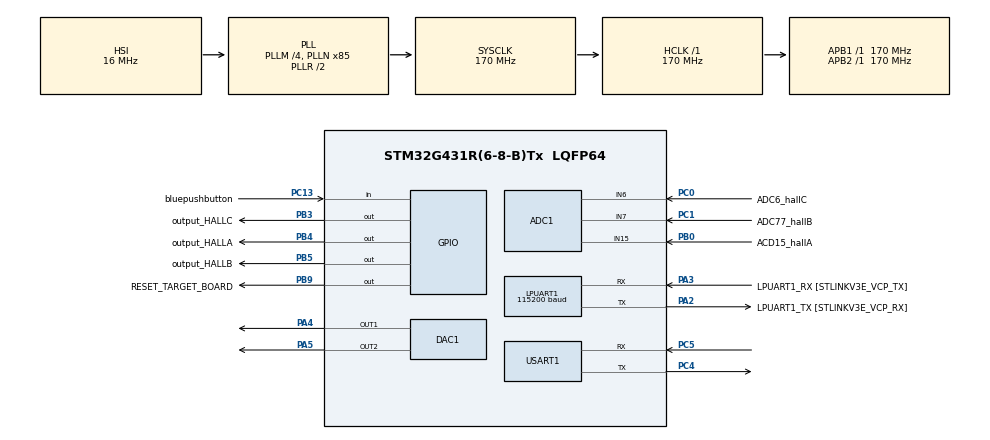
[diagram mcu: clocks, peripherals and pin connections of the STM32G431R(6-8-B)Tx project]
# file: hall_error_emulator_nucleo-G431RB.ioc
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ADC1.Channel-0\#ChannelRegularConversion=ADC_CHANNEL_15
ADC1.Channel-1\#ChannelRegularConversion=ADC_CHANNEL_7
ADC1.Channel-2\#ChannelRegularConversion=ADC_CHANNEL_6
ADC1.ContinuousConvMode=ENABLE
ADC1.DMAContinuousRequests=ENABLE
ADC1.ExternalTrigConv=ADC_EXTERNALTRIG_T8_TRGO
ADC1.NbrOfConversion=3
ADC1.NbrOfConversionFlag=1
ADC1.OffsetNumber-0\#ChannelRegularConversion=ADC_OFFSET_NONE
ADC1.OffsetNumber-1\#ChannelRegularConversion=ADC_OFFSET_NONE
ADC1.OffsetNumber-2\#ChannelRegularConversion=ADC_OFFSET_NONE
ADC1.Rank-0\#ChannelRegularConversion=1
ADC1.Rank-1\#ChannelRegularConversion=2
ADC1.Rank-2\#ChannelRegularConversion=3
ADC1.SamplingTime-0\#ChannelRegularConversion=ADC_SAMPLETIME_2CYCLES_5
ADC1.SamplingTime-1\#ChannelRegularConversion=ADC_SAMPLETIME_2CYCLES_5
ADC1.SamplingTime-2\#ChannelRegularConversion=ADC_SAMPLETIME_2CYCLES_5
ADC1.master=1
DAC1.DAC_Channel-DAC_OUT2=DAC_CHANNEL_2
DAC1.DAC_Trigger_OUT1-DAC_OUT1=DAC_TRIGGER_T8_TRGO
DAC1.DAC_Trigger_OUT2-DAC_OUT2=DAC_TRIGGER_T8_TRGO
Dma.ADC1.4.Direction=DMA_PERIPH_TO_MEMORY
Dma.ADC1.4.EventEnable=DISABLE
Dma.ADC1.4.Instance=DMA1_Channel5
Dma.ADC1.4.MemDataAlignment=DMA_MDATAALIGN_WORD
Dma.ADC1.4.MemInc=DMA_MINC_ENABLE
Dma.ADC1.4.Mode=DMA_CIRCULAR
Dma.ADC1.4.PeriphDataAlignment=DMA_PDATAALIGN_WORD
Dma.ADC1.4.PeriphInc=DMA_PINC_DISABLE
Dma.ADC1.4.Polarity=HAL_DMAMUX_REQ_GEN_RISING
Dma.ADC1.4.Priority=DMA_PRIORITY_LOW
Dma.ADC1.4.RequestNumber=1
Dma.ADC1.4.SignalID=NONE
Dma.ADC1.4.SyncEnable=DISABLE
Dma.ADC1.4.SyncPolarity=HAL_DMAMUX_SYNC_NO_EVENT
Dma.ADC1.4.SyncRequestNumber=1
Dma.ADC1.4.SyncSignalID=NONE
Dma.DAC1_CH1.2.Direction=DMA_MEMORY_TO_PERIPH
Dma.DAC1_CH1.2.EventEnable=DISABLE
Dma.DAC1_CH1.2.Instance=DMA1_Channel3
Dma.DAC1_CH1.2.MemDataAlignment=DMA_MDATAALIGN_WORD
Dma.DAC1_CH1.2.MemInc=DMA_MINC_ENABLE
Dma.DAC1_CH1.2.Mode=DMA_CIRCULAR
Dma.DAC1_CH1.2.PeriphDataAlignment=DMA_PDATAALIGN_WORD
Dma.DAC1_CH1.2.PeriphInc=DMA_PINC_DISABLE
Dma.DAC1_CH1.2.Polarity=HAL_DMAMUX_REQ_GEN_RISING
Dma.DAC1_CH1.2.Priority=DMA_PRIORITY_MEDIUM
Dma.DAC1_CH1.2.RequestNumber=1
Dma.DAC1_CH1.2.SignalID=NONE
Dma.DAC1_CH1.2.SyncEnable=DISABLE
Dma.DAC1_CH1.2.SyncPolarity=HAL_DMAMUX_SYNC_NO_EVENT
Dma.DAC1_CH1.2.SyncRequestNumber=1
Dma.DAC1_CH1.2.SyncSignalID=NONE
Dma.DAC1_CH2.3.Direction=DMA_MEMORY_TO_PERIPH
Dma.DAC1_CH2.3.EventEnable=DISABLE
Dma.DAC1_CH2.3.Instance=DMA1_Channel4
Dma.DAC1_CH2.3.MemDataAlignment=DMA_MDATAALIGN_WORD
Dma.DAC1_CH2.3.MemInc=DMA_MINC_ENABLE
Dma.DAC1_CH2.3.Mode=DMA_CIRCULAR
Dma.DAC1_CH2.3.PeriphDataAlignment=DMA_PDATAALIGN_WORD
Dma.DAC1_CH2.3.PeriphInc=DMA_PINC_DISABLE
Dma.DAC1_CH2.3.Polarity=HAL_DMAMUX_REQ_GEN_RISING
Dma.DAC1_CH2.3.Priority=DMA_PRIORITY_MEDIUM
Dma.DAC1_CH2.3.RequestNumber=1
Dma.DAC1_CH2.3.SignalID=NONE
Dma.DAC1_CH2.3.SyncEnable=DISABLE
Dma.DAC1_CH2.3.SyncPolarity=HAL_DMAMUX_SYNC_NO_EVENT
Dma.DAC1_CH2.3.SyncRequestNumber=1
Dma.DAC1_CH2.3.SyncSignalID=NONE
Dma.LPUART1_RX.0.Direction=DMA_PERIPH_TO_MEMORY
Dma.LPUART1_RX.0.EventEnable=DISABLE
Dma.LPUART1_RX.0.Instance=DMA1_Channel1
Dma.LPUART1_RX.0.MemDataAlignment=DMA_MDATAALIGN_BYTE
Dma.LPUART1_RX.0.MemInc=DMA_MINC_ENABLE
Dma.LPUART1_RX.0.Mode=DMA_CIRCULAR
Dma.LPUART1_RX.0.PeriphDataAlignment=DMA_PDATAALIGN_BYTE
Dma.LPUART1_RX.0.PeriphInc=DMA_PINC_DISABLE
Dma.LPUART1_RX.0.Polarity=HAL_DMAMUX_REQ_GEN_RISING
Dma.LPUART1_RX.0.Priority=DMA_PRIORITY_LOW
Dma.LPUART1_RX.0.RequestNumber=1
Dma.LPUART1_RX.0.SignalID=NONE
Dma.LPUART1_RX.0.SyncEnable=DISABLE
Dma.LPUART1_RX.0.SyncPolarity=HAL_DMAMUX_SYNC_NO_EVENT
Dma.LPUART1_RX.0.SyncRequestNumber=1
Dma.LPUART1_RX.0.SyncSignalID=NONE
Dma.LPUART1_TX.1.Direction=DMA_MEMORY_TO_PERIPH
Dma.LPUART1_TX.1.EventEnable=DISABLE
Dma.LPUART1_TX.1.Instance=DMA1_Channel2
Dma.LPUART1_TX.1.MemDataAlignment=DMA_MDATAALIGN_BYTE
Dma.LPUART1_TX.1.MemInc=DMA_MINC_ENABLE
Dma.LPUART1_TX.1.Mode=DMA_NORMAL
Dma.LPUART1_TX.1.PeriphDataAlignment=DMA_PDATAALIGN_BYTE
Dma.LPUART1_TX.1.PeriphInc=DMA_PINC_DISABLE
Dma.LPUART1_TX.1.Polarity=HAL_DMAMUX_REQ_GEN_RISING
Dma.LPUART1_TX.1.Priority=DMA_PRIORITY_LOW
Dma.LPUART1_TX.1.RequestNumber=1
Dma.LPUART1_TX.1.SignalID=NONE
Dma.LPUART1_TX.1.SyncEnable=DISABLE
Dma.LPUART1_TX.1.SyncPolarity=HAL_DMAMUX_SYNC_NO_EVENT
Dma.LPUART1_TX.1.SyncRequestNumber=1
Dma.LPUART1_TX.1.SyncSignalID=NONE
Dma.Request0=LPUART1_RX
Dma.Request1=LPUART1_TX
Dma.Request2=DAC1_CH1
Dma.Request3=DAC1_CH2
Dma.Request4=ADC1
LPUART1.BaudRate=115200
Mcu.Family=STM32G4
Mcu.Name=STM32G431R(6-8-B)Tx
Mcu.Package=LQFP64
Mcu.UserConstants=PREESCALER_TIM8,170-1;COUNTER_TIM8,50-1
NVIC.DMA1_Channel1_IRQn=true\:0\:0\:false\:false\:true\:false\:true\:true
NVIC.DMA1_Channel2_IRQn=true\:0\:0\:false\:false\:true\:false\:true\:true
NVIC.DMA1_Channel3_IRQn=true\:0\:0\:false\:false\:true\:false\:true\:true
NVIC.DMA1_Channel4_IRQn=true\:0\:0\:false\:false\:true\:false\:true\:true
NVIC.DMA1_Channel5_IRQn=true\:0\:0\:false\:false\:true\:false\:true\:true
NVIC.LPUART1_IRQn=true\:1\:0\:true\:false\:true\:true\:true\:true
NVIC.PriorityGroup=NVIC_PRIORITYGROUP_4
NVIC.TIM8_UP_IRQn=true\:0\:0\:false\:false\:true\:true\:true\:true
PA13.GPIO_Label=T_SWDIO
PA13.Mode=Serial_Wire
PA13.Signal=SYS_JTMS-SWDIO
PA14.GPIO_Label=T_SWCLK
PA14.Mode=Serial_Wire
PA14.Signal=SYS_JTCK-SWCLK
PA2.GPIO_Label=LPUART1_TX [STLINKV3E_VCP_RX]
PA2.Mode=Asynchronous
PA2.Signal=LPUART1_TX
PA3.GPIO_Label=LPUART1_RX [STLINKV3E_VCP_TX]
PA3.Mode=Asynchronous
PA3.Signal=LPUART1_RX
PA4.Signal=COMP_DAC11_group
PA5.Signal=COMP_DAC12_group
PB0.GPIO_Label=ACD15_hallA
PB0.Mode=IN15-Single-Ended
PB0.Signal=ADC1_IN15
PB3.GPIO_Label=output_HALLC
PB3.Signal=GPIO_Output
PB4.GPIO_Label=output_HALLA
PB4.Signal=GPIO_Output
PB5.GPIO_Label=output_HALLB
PB5.Signal=GPIO_Output
PB9.GPIO_Label=RESET_TARGET_BOARD
PB9.GPIO_PuPd=GPIO_PULLUP
PB9.PinState=GPIO_PIN_SET
PB9.Signal=GPIO_Output
PC0.GPIO_Label=ADC6_hallC
PC0.Mode=IN6-Single-Ended
PC0.Signal=ADC1_IN6
PC1.GPIO_Label=ADC77_hallB
PC1.Mode=IN7-Single-Ended
PC1.Signal=ADC1_IN7
PC13.GPIO_Label=bluepushbutton
PC13.Signal=GPIO_Input
PC4.Mode=Asynchronous
PC4.Signal=USART1_TX
PC5.Mode=Asynchronous
PC5.Signal=USART1_RX
PF0-OSC_IN.Mode=HSE-External-Oscillator
PF0-OSC_IN.Signal=RCC_OSC_IN
PF1-OSC_OUT.Mode=HSE-External-Oscillator
PF1-OSC_OUT.Signal=RCC_OSC_OUT
ProjectManager.HeapSize=0x200
ProjectManager.StackSize=0x400
ProjectManager.TargetToolchain=STM32CubeIDE
RCC.ADC12Freq_Value=170000000
RCC.AHBFreq_Value=170000000
RCC.APB1Freq_Value=170000000
RCC.APB1TimFreq_Value=170000000
RCC.APB2Freq_Value=170000000
RCC.APB2TimFreq_Value=170000000
RCC.CortexFreq_Value=170000000
RCC.EXTERNAL_CLOCK_VALUE=12288000
RCC.HCLKFreq_Value=170000000
RCC.HSE_VALUE=24000000
RCC.HSI48_VALUE=48000000
RCC.HSI_VALUE=16000000
RCC.LSE_VALUE=32768
RCC.PLLM=RCC_PLLM_DIV4
RCC.PLLN=85
RCC.RTCClockSelection=RCC_RTCCLKSOURCE_LSE
RCC.SYSCLKFreq_VALUE=170000000
RCC.SYSCLKSource=RCC_SYSCLKSOURCE_PLLCLK
RCC.USBFreq_Value=170000000
RCC.VCOOutputFreq_Value=340000000
SH.COMP_DAC11_group.0=DAC1_OUT1,DAC_OUT1
SH.COMP_DAC12_group.0=DAC1_OUT2,DAC_OUT2
TIM8.PeriodNoDither=COUNTER_TIM8
TIM8.Prescaler=PREESCALER_TIM8
TIM8.TIM_MasterOutputTrigger=TIM_TRGO_UPDATE
TIM8.TIM_MasterOutputTrigger2=TIM_TRGO2_RESET
USART1.VirtualMode-Asynchronous=VM_ASYNC
VP_SYS_VS_DBSignals.Mode=DisableDeadBatterySignals
VP_TIM8_VS_ClockSourceINT.Mode=Internal
board=NUCLEO-G431RB

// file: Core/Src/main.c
/* USER CODE BEGIN Header */
/**
  ******************************************************************************
  * @file           : main.c
  * @brief          : Main program body
  ******************************************************************************
  * @attention
  *
  * Copyright (c) 2023 STMicroelectronics.
  * All rights reserved.
  *
  * This software is licensed under terms that can be found in the LICENSE file
  * in the root directory of this software component.
  * If no LICENSE file comes with this software, it is provided AS-IS.
  *
  ******************************************************************************
  */
/* USER CODE END Header */
#include "main.h"
#include "adc.h"
#include "dac.h"
#include "dma.h"
#include "usart.h"
#include "tim.h"
#include "gpio.h"

/* USER CODE BEGIN Includes */
#include "hall_swapper.h"
#include "user_interface.h"
#include "wave_emulator.h"
/* USER CODE END Includes */

void SystemClock_Config(void);

int main(void)
{

  /* MCU Configuration--------------------------------------------------------*/

  /* Reset of all peripherals, Initializes the Flash interface and the Systick. */
  HAL_Init();

  /* Configure the system clock */
  SystemClock_Config();

  /* Initialize all configured peripherals */
  MX_GPIO_Init();
  MX_DMA_Init();
  MX_DAC1_Init();
  MX_LPUART1_UART_Init();
  MX_TIM8_Init();
  MX_USART1_UART_Init();
  MX_ADC1_Init();
  /* USER CODE BEGIN 2 */
  ui_uart_init();
  startADCs();
  HAL_TIM_Base_Start_IT(&htim8); //start 20Khz timer with enabled interruption

  /* USER CODE END 2 */

  /* Infinite loop */
  /* USER CODE BEGIN WHILE */
  while (1)
  {
	ui_uart_listen();
	emulation();

    /* USER CODE END WHILE */

  }
}

void SystemClock_Config(void)
{
  RCC_OscInitTypeDef RCC_OscInitStruct = {0};
  RCC_ClkInitTypeDef RCC_ClkInitStruct = {0};

  /** Configure the main internal regulator output voltage
  */
  HAL_PWREx_ControlVoltageScaling(PWR_REGULATOR_VOLTAGE_SCALE1_BOOST);

  /** Initializes the RCC Oscillators according to the specified parameters
  * in the RCC_OscInitTypeDef structure.
  */
  RCC_OscInitStruct.OscillatorType = RCC_OSCILLATORTYPE_HSI;
  RCC_OscInitStruct.HSIState = RCC_HSI_ON;
  RCC_OscInitStruct.HSICalibrationValue = RCC_HSICALIBRATION_DEFAULT;
  RCC_OscInitStruct.PLL.PLLState = RCC_PLL_ON;
  RCC_OscInitStruct.PLL.PLLSource = RCC_PLLSOURCE_HSI;
  RCC_OscInitStruct.PLL.PLLM = RCC_PLLM_DIV4;
  RCC_OscInitStruct.PLL.PLLN = 85;
  RCC_OscInitStruct.PLL.PLLP = RCC_PLLP_DIV2;
  RCC_OscInitStruct.PLL.PLLQ = RCC_PLLQ_DIV2;
  RCC_OscInitStruct.PLL.PLLR = RCC_PLLR_DIV2;
  if (HAL_RCC_OscConfig(&RCC_OscInitStruct) != HAL_OK)
  {
    Error_Handler();
  }

  /** Initializes the CPU, AHB and APB buses clocks
  */
  RCC_ClkInitStruct.ClockType = RCC_CLOCKTYPE_HCLK|RCC_CLOCKTYPE_SYSCLK
                              |RCC_CLOCKTYPE_PCLK1|RCC_CLOCKTYPE_PCLK2;
  RCC_ClkInitStruct.SYSCLKSource = RCC_SYSCLKSOURCE_PLLCLK;
  RCC_ClkInitStruct.AHBCLKDivider = RCC_SYSCLK_DIV1;
  RCC_ClkInitStruct.APB1CLKDivider = RCC_HCLK_DIV1;
  RCC_ClkInitStruct.APB2CLKDivider = RCC_HCLK_DIV1;

  if (HAL_RCC_ClockConfig(&RCC_ClkInitStruct, FLASH_LATENCY_4) != HAL_OK)
  {
    Error_Handler();
  }
}

void Error_Handler(void)
{
  __disable_irq();
  while (1)
  {
  }
}
